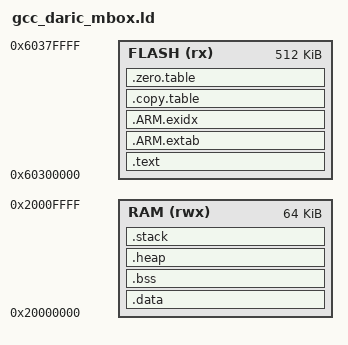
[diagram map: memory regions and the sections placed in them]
/******************************************************************************
 * @file     gcc_arm.ld
 * @brief    GNU Linker Script for Cortex-M based device
 * @version  V2.2.0
 * @date     20. January 2021
 ******************************************************************************/
/*
 * Copyright (c) 2009-2021 Arm Limited. All rights reserved.
 *
 * SPDX-License-Identifier: Apache-2.0
 */

__ROM_BASE = 0x60300000;
__ROM_SIZE = 0x00080000;

__RAM_BASE = 0x20000000;
__RAM_SIZE = 0x00010000;

__STACK_SIZE = 0x00002000;
__HEAP_SIZE  = 0x00000800;
__STACKSEAL_SIZE = 0;

/*
 * <<< MODIFIED: Define the '_vectors' symbol directly >>>
 * The ThreadX port expects a symbol named '_vectors' pointing to the start
 * of the vector table. We define it here as the base address of FLASH.
 */
_vectors = __ROM_BASE;


MEMORY
{
  FLASH (rx)  : ORIGIN = __ROM_BASE, LENGTH = __ROM_SIZE
  RAM   (rwx) : ORIGIN = __RAM_BASE, LENGTH = __RAM_SIZE
}

ENTRY(Reset_Handler)

SECTIONS
{
  .text :
  {
    KEEP(*(.vectors))
    *(.text*)

    KEEP(*(.init))
    KEEP(*(.fini))

    /* .ctors */
    *crtbegin.o(.ctors)
    *crtbegin?.o(.ctors)
    *(EXCLUDE_FILE(*crtend?.o *crtend.o) .ctors)
    *(SORT(.ctors.*))
    *(.ctors)

    /* .dtors */
    *crtbegin.o(.dtors)
    *crtbegin?.o(.dtors)
    *(EXCLUDE_FILE(*crtend?.o *crtend.o) .dtors)
    *(SORT(.dtors.*))
    *(.dtors)

    *(.rodata*)

    KEEP(*(.eh_frame*))
    KEEP(*(.note.gnu.build-id))
  } > FLASH

  .ARM.extab :
  {
    *(.ARM.extab* .gnu.linkonce.armextab.*)
  } > FLASH

  __exidx_start = .;
  .ARM.exidx :
  {
    *(.ARM.exidx* .gnu.linkonce.armexidx.*)
  } > FLASH
  __exidx_end = .;

  .copy.table :
  {
    . = ALIGN(8);
    __copy_table_start__ = .;
    LONG (__etext)
    LONG (__data_start__)
    LONG ((__data_end__ - __data_start__) / 4)
    __copy_table_end__ = .;
  } > FLASH

  .zero.table :
  {
    . = ALIGN(8);
    __zero_table_start__ = .;
    __zero_table_end__ = .;
  } > FLASH

  __etext = ALIGN (8);

  .data : AT (__etext)
  {
    __data_start__ = .;
    *(vtable)
    *(.data)
    *(.data.*)

    . = ALIGN(8);
    /* preinit data */
    PROVIDE_HIDDEN (__preinit_array_start = .);
    KEEP(*(.preinit_array))
    PROVIDE_HIDDEN (__preinit_array_end = .);

    . = ALIGN(8);
    /* init data */
    PROVIDE_HIDDEN (__init_array_start = .);
    KEEP(*(SORT(.init_array.*)))
    KEEP(*(.init_array))
    PROVIDE_HIDDEN (__init_array_end = .);

    . = ALIGN(8);
    /* finit data */
    PROVIDE_HIDDEN (__fini_array_start = .);
    KEEP(*(SORT(.fini_array.*)))
    KEEP(*(.fini_array))
    PROVIDE_HIDDEN (__fini_array_end = .);

    KEEP(*(.jcr*))
    . = ALIGN(8);
    /* All data end */
    __data_end__ = .;

  } > RAM

  .bss :
  {
    . = ALIGN(8);
    __bss_start__ = .;
    *(.bss)
    *(.bss.*)
    *(COMMON)
    . = ALIGN(8);
    __bss_end__ = .;
    /* Define the symbol for the end of RAM usage */
    __RAM_segment_used_end__ = .;
  } > RAM AT > RAM

  .heap (COPY) :
  {
    . = ALIGN(8);
    __end__ = .;
    PROVIDE(end = .);
    . = . + __HEAP_SIZE;
    . = ALIGN(8);
    __HeapLimit = .;
  } > RAM

  .stack (ORIGIN(RAM) + LENGTH(RAM) - __STACK_SIZE - __STACKSEAL_SIZE) (COPY) :
  {
    . = ALIGN(8);
    __StackLimit = .;
    . = . + __STACK_SIZE;
    . = ALIGN(8);
    __StackTop = .;
  } > RAM
  PROVIDE(__stack = __StackTop);

  /* Check if data + heap + stack exceeds RAM limit */
  ASSERT(__StackLimit >= __HeapLimit, "region RAM overflowed with stack")
}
